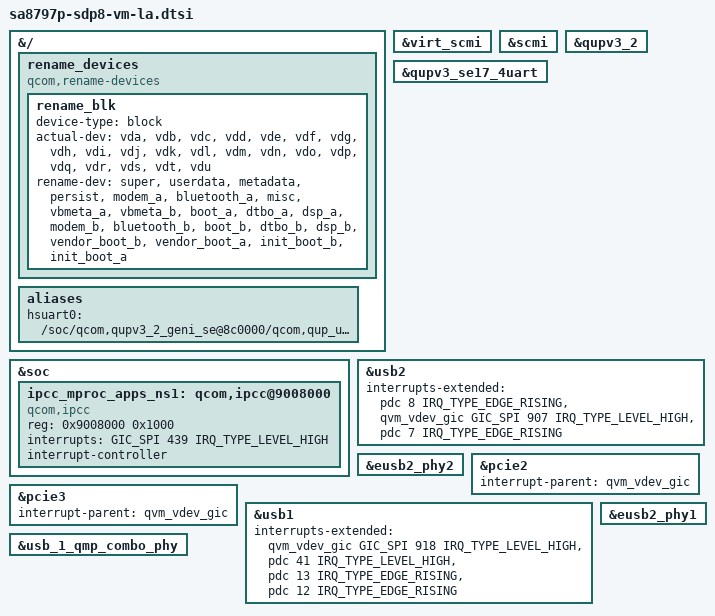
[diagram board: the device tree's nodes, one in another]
// SPDX-License-Identifier: BSD-3-Clause
/*
 * Copyright (c) Qualcomm Technologies, Inc. and/or its subsidiaries.
 */

#include <dt-bindings/mailbox/qcom-ipcc.h>
#include <dt-bindings/soc/qcom,ipcc.h>
#include <dt-bindings/mailbox/qcom-ipcc-sa8797p.h>

&{/} {
	rename_devices: rename_devices {
		compatible = "qcom,rename-devices";
		rename_blk: rename_blk {
			device-type = "block";
			actual-dev = "vda", "vdb", "vdc",
					"vdd", "vde", "vdf",
					"vdg", "vdh", "vdi",
					"vdj", "vdk", "vdl",
					"vdm", "vdn", "vdo",
					"vdp", "vdq", "vdr",
					"vds", "vdt", "vdu";
			rename-dev = "super", "userdata", "metadata",
					"persist", "modem_a","bluetooth_a",
					"misc", "vbmeta_a", "vbmeta_b",
					"boot_a", "dtbo_a", "dsp_a",
					"modem_b", "bluetooth_b", "boot_b",
					"dtbo_b", "dsp_b", "vendor_boot_b",
					"vendor_boot_a", "init_boot_b", "init_boot_a";
		};
	};
	aliases: aliases {
		hsuart0 = "/soc/qcom,qupv3_2_geni_se@8c0000/qcom,qup_uart@88c000";
	};
};

&soc {
	ipcc_mproc_apps_ns1: qcom,ipcc@9008000 {
		compatible = "qcom,ipcc";
		reg = <0x9008000 0x1000>;
		interrupts = <GIC_SPI 439 IRQ_TYPE_LEVEL_HIGH>;
		interrupt-controller;
		#interrupt-cells = <3>;
		#mbox-cells = <2>;
		status = "ok";
	};
};

&virt_scmi {
	status = "ok";
};

&scmi {
	status = "ok";
};

&qupv3_2 {
	status = "ok";
};

&qupv3_se17_4uart {
	status = "ok";
};

&usb2 {
	interrupts-extended = <&pdc 8 IRQ_TYPE_EDGE_RISING>,
			<&qvm_vdev_gic GIC_SPI 907 IRQ_TYPE_LEVEL_HIGH>,
			<&pdc 7 IRQ_TYPE_EDGE_RISING>;
	status = "ok";
};

&eusb2_phy2 {
	status = "ok";
};

&pcie2 {
	interrupt-parent = <&qvm_vdev_gic>;
	status = "ok";
};

&pcie3 {
	interrupt-parent = <&qvm_vdev_gic>;
	status = "ok";
};

&usb1 {
	interrupts-extended = <&qvm_vdev_gic GIC_SPI 918 IRQ_TYPE_LEVEL_HIGH>,
			<&pdc 41 IRQ_TYPE_LEVEL_HIGH>,
			<&pdc 13 IRQ_TYPE_EDGE_RISING>,
			<&pdc 12 IRQ_TYPE_EDGE_RISING>;
	status = "ok";
};

&usb_1_qmp_combo_phy {
	status = "ok";
};

&eusb2_phy1 {
	status = "ok";
};
